# tviibh16m register map
Vendor: Infineon Technologies; Series: TVIIBH16M; File version: 1.0
CPU: CM7 r0p1, little endian, MPU, FPU, double-precision FPU, I-cache, D-cache, VTOR, ITCM, DTCM, 3 interrupt priority bits, 16 interrupts
Registers are 32-bit, read-write, reset 0x0 unless marked. A register's access mark holds for its fields unless they carry their own. Offsets are from the block's base; [hi:lo] are bit positions; lines under a group give offsets from that group; {n}, {i} and the like mark numbered series.

## EVTGEN0 — Event generator
Base 0x403F0000
0x00 CTL — Control
  [31] ENABLED — IP enable: '0': Disabled. All non-retention registers (command and status registers) are reset to their default value when the IP is disabled. All retention registers retain their value when the IP is disabled. '1': Enabled.
    0=DISABLED (N/A); 1=ENABLED (N/A)
0x04 COMP0_STATUS ro — Comparator structures comparator 0 status
  [15:0] COMP0_OUT — Active comparator 'comp0_out[]' outputs.
0x08 COMP1_STATUS ro — Comparator structures comparator 1 status
  [15:0] COMP1_OUT — DeepSleep comparator 'comp1_out_lf[]' outputs (synchronized from clk_lf to the IP clock).
0x10 COUNTER_STATUS ro
  [31] VALID — Active counter validity: '0': Invalid. '1': Valid. The COUNTER register field INT32 is only valid when VALID is '1'. The COUNTER_STATUS and COUNTER registers are non-retention registers; i.e. the COUNTER_STATUS and COUNTER registers are reset during DeepSleep power mode. After entering the Active power mode, the Active counter is initialized with the DeepSleep counter. This initialization may take up to 1 clk_lf cycle.
0x14 COUNTER ro reset not defined
  [31:0] INT32 — Active counter 'counter_int[31:0]' on clk_ref_div.
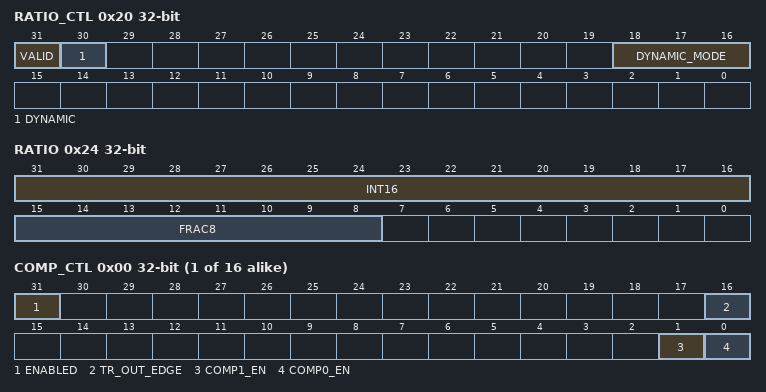
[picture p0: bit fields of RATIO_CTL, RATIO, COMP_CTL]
0x20 RATIO_CTL — Ratio control
  [31] VALID — Ratio value valid: '0': Invalid. '1': Valid. The RATIO register fields INT16 and FRAC8 are only valid when VALID is '1'.
  [30] DYNAMIC — Specifies if RATIO_CTL.VALID and RATIO are under SW or HW control: '0': SW control. '1: HW control. Auto calibration is used to derive the RATIO value. HW measures the number of clk_ref_div cycles per clk_lf cycle. This measurement is combined with the current ratio value to calculate a new ratio value.
  [18:16] DYNAMIC_MODE — Weighted average calculation (only used when DYNAMIC is '1'): '0': new RATIO value = (RATIO + measurement + 1) / 2. '1': new RATIO value = (3*RATIO + measurement + 2) / 4. '2': new RATIO value = (7*RATIO + measurement + 4) / 8. '3': new RATIO value = (15*RATIO + measurement + 8) / 16. '4': new RATIO value = (31*RATIO + measurement + 16) / 32. '5': new RATIO value = (63*RATIO + measurement + 32) / 64. '6': new RATIO value = (127*RATIO + measurement + 64) / 128. '7': new RATIO value = (255*RATIO + measurement + 128) / 256. Note: 'measurement' (integer component only) is defined as: 256 * 'number of measured clk_ref_div cycles per clk_lf cycle'. The RATIO value (integer and fractional component) is defined as: 256*RATIO.INT16 + RATIO.FRAC8 (RATIO.INT16 = RATIO >> 8 and RATIO.FRAC8 = RATIO percent 256).
0x24 RATIO reset not defined
  [31:16] INT16 — Integer component of ratio value.
  [15:8] FRAC8 — Fractional component of ratio value.
0x30 REF_CLOCK_CTL — Reference clock control
  [7:0] INT_DIV — Divider control for clk_ref_div: '0': Divide by 1. ... '255': Divide by '256'. Fclk_ref_div = Fclk_ref / (INT_DIV + 1)
0x700 INTR — Interrupt
  [15:0] COMP0 write-1-clears — This interrupt cause field is activated (HW sets the field to '1') when a comparator 0 event is generated (Active counter 'counter_int[31:0]' becomes greater or equal to COMP0.INT[31:0]).
0x704 INTR_SET — Interrupt set
  [15:0] COMP0 write-1-sets — SW writes a '1' to this field to set the corresponding field in the INTR register.
0x708 INTR_MASK — Interrupt mask
  [15:0] COMP0 — Mask bit for corresponding field in the INTR register.
0x70C INTR_MASKED ro — Interrupt masked
  [15:0] COMP0 — Logical and of corresponding INTR and INTR_MASK fields.
0x710 INTR_DPSLP — DeepSleep interrupt
  [15:0] COMP1 write-1-clears — This interrupt cause field is activated (HW sets the field to '1') when a comparator 1 event is generated (DeepSleep counter 'counter_int_lf[31:0]' becomes greater or equal to COMP1.INT[31:0]).
0x714 INTR_DPSLP_SET — DeepSleep interrupt set
  [15:0] COMP1 write-1-sets — SW writes a '1' to this field to set the corresponding field in the INTR register.
0x718 INTR_DPSLP_MASK — DeepSleep interrupt mask
  [15:0] COMP1 — Mask bit for corresponding field in the INTR register.
0x71C INTR_DPSLP_MASKED ro — DeepSleep interrupt masked
  [15:0] COMP1 — Logical and of corresponding INTR and INTR_MASK fields.
{0x800+0x20*i} COMP_STRUCT[{i}] (i=0..15) group — Comparator structure
  0x00 COMP_CTL — Comparator control
    [31] ENABLED — Comparator structure enable: '0': Disabled. '1': Enabled.
    [16] TR_OUT_EDGE — Specifies the 'tr_out' output trigger: '0': The trigger is a level sensitive trigger. The Active comparator output ('comp0_out') is reflected on 'tr_out'. '1': The trigger is an edge sensitive trigger. Activation of the Active comparator output (rising edge on 'comp0_out') results in a two cycle '1'/high pulse on 'tr_out'.
    [1] COMP1_EN — DeepSleep comparator (COMP1) enable: '0': Disabled. The comparator output 'comp1_out_lf' is '0'. '1': Enabled.
    [0] COMP0_EN — Active comparator (COMP0) enable: '0': Disabled. The comparator output 'comp0_out' is '0'. '1': Enabled.
  0x04 COMP0 reset not defined — Comparator 0 (Active functionality)
    [31:0] INT32 — This value is a 32-bit unsigned integer in the range [0, 2^32-1]. The comparator 'comp0_out' output is activated when the Active counter 'counter_int[31:0]' becomes greater or equal to COMP0. Note: SW must ensure that COMP_CTL.COMP_EN[0] is '0' when COMP0 is written.
  0x08 COMP1 reset not defined — Comparator 1 (DeepSleep functionality)
    [31:0] INT32 — This value is a 32-bit unsigned integer in the range [0, 2^32-1]. The comparator 'comp1_out_lf' output is activated when the DeepSleep counter 'counter_int_lf[31:0]' becomes greater or equal to COMP1. Note: SW must ensure that COMP_CTL.COMP_EN[1] is '0' when COMP1 is written.
